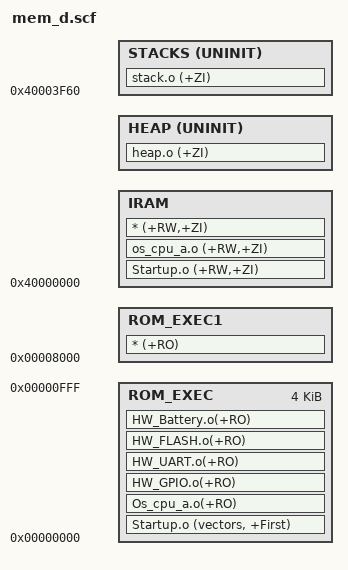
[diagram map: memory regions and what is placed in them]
;/****************************************Copyright (c)**************************************************
;**描        述: 有片内FLASH分散加载文件，决定各个代码段和数据段的存储位置（用于产品）
;**              每个工程应当有独立的这个文件的拷贝，并进行相应的修改   
;********************************************************************************************************/

ROM_LOAD 0x0000
{
	ROM_EXEC 0x0000 0x1000
	{
	    Startup.o (vectors, +First)
	    Os_cpu_a.o(+RO)
	    HW_GPIO.o(+RO)
	    HW_UART.o(+RO)
	    HW_FLASH.o(+RO)
	    HW_Battery.o(+RO)
	} 	
	IRAM 0x40000000
	{
	    Startup.o (+RW,+ZI)
	    os_cpu_a.o (+RW,+ZI)
	    * (+RW,+ZI)
	}
	
	HEAP +0 UNINIT
	{
	    heap.o (+ZI)
	}
	
	STACKS 0x40003f60 UNINIT
	{
	    stack.o (+ZI)
	}
}

ROM_LOAD1  0x8000
{
	ROM_EXEC1 0x8000
	{
	    * (+RO)	
	}	
}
